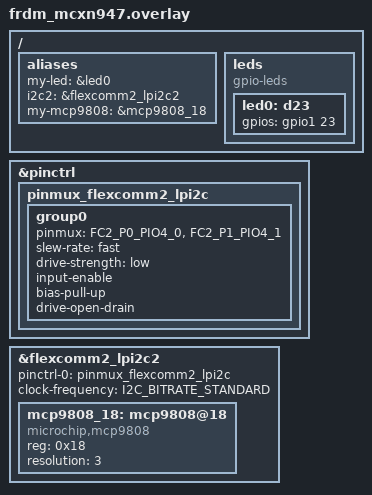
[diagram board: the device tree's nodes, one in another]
/ {
    aliases {
        my-led = &led0;
        i2c2 = &flexcomm2_lpi2c2;
        my-mcp9808 = &mcp9808_18;
    };

    leds {
        compatible = "gpio-leds";
        led0: d23 {
            gpios = <&gpio1 23 GPIO_ACTIVE_HIGH>;
        };
    };
};

&pinctrl {
    pinmux_flexcomm2_lpi2c: pinmux_flexcomm2_lpi2c {
        group0 {
            pinmux = <FC2_P0_PIO4_0>, <FC2_P1_PIO4_1>;  // SDA, SCL pins
			slew-rate = "fast";
			drive-strength = "low";
			input-enable;
			bias-pull-up;
			drive-open-drain;
        };
    };
};

&flexcomm2_lpi2c2 {
    status = "okay";
    pinctrl-0 = <&pinmux_flexcomm2_lpi2c>;
    pinctrl-names = "default";
    clock-frequency = <I2C_BITRATE_STANDARD>;

    mcp9808_18: mcp9808@18 {
        compatible = "microchip,mcp9808";
        reg = <0x18>;
        resolution = <3>;
        status = "okay";
    };
};

